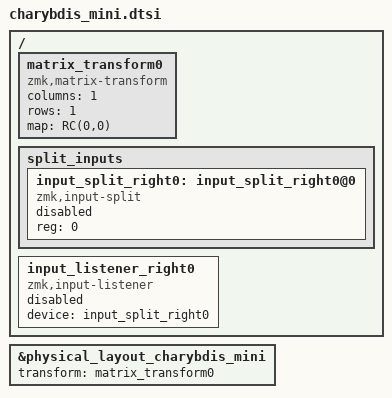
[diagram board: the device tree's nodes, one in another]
#include "charybdis_mini-layouts.dtsi"
#include <dt-bindings/zmk/matrix_transform.h>

/ {
    matrix_transform0: matrix_transform0 {
        compatible = "zmk,matrix-transform";
        columns = <1>;
        rows = <1>;
        map = <
            RC(0,0)
        >;
    };
};

&physical_layout_charybdis_mini {
    transform = <&matrix_transform0>;
};

// Input devices
/ {
    split_inputs {
        #address-cells = <1>;
        #size-cells = <0>;

        input_split_right0: input_split_right0@0 {
            compatible = "zmk,input-split";
            reg = <0>;
            status = "disabled";
        };
    };

    input_listener_right0: input_listener_right0 {
        compatible = "zmk,input-listener";
        status = "disabled";
        device = <&input_split_right0>;
    };
};

